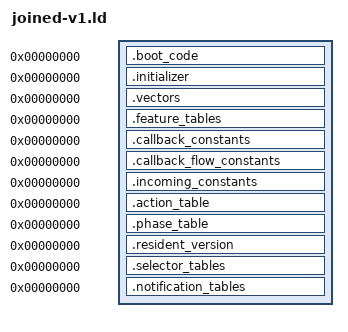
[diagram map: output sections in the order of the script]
OUTPUT_ARCH(riscv)
SECTIONS
{
 .boot_code 0 : SUBALIGN(2) { *(.boot_code)
  *(.text.tsl9_feature_external_a054)
  *(.text.tsl9_input_state_decoders_block_a066)
  *(.text.tsl9_input_state_decoders_block_a06a)
  *(.text.tsl9_input_state_decoders_block_a06e)
  *(.text.tsl9_input_state_decoders_block_a072)
  *(.text.tsl9_input_state_decoders_block_a082)
  *(.text.tsl9_input_state_decoders_block_a086)
  *(.text.tsl9_input_state_decoders_block_a08e)
  *(.text.tsl9_input_state_decoders_block_a098)
  *(.text.tsl9_input_state_decoders_block_a0a0)
  *(.text.tsl9_input_state_decoders_block_a0ac)
  *(.text.tsl9_input_state_decoders_block_a0ae)
  *(.text.tsl9_input_state_decoders_block_a0c4)
  *(.text.tsl9_input_state_decoders_block_a0c8)
  *(.text.tsl9_input_state_decoders_block_a0cc)
  *(.text.tsl9_input_state_decoders_block_a0d0)
  *(.text.tsl9_input_state_decoders_block_a0d4)
  *(.text.tsl9_input_state_decoders_block_a0e2)
  *(.text.tsl9_input_state_decoders_block_a0e6)
  *(.text.tsl9_input_state_decoders_block_a0ee)
  *(.text.tsl9_input_state_decoders_block_a100)
  *(.text.tsl9_input_state_decoders_block_a114)
  *(.text.tsl9_input_state_decoders_block_a132)
  *(.text.tsl9_input_state_decoders_block_a136)
  *(.text.tsl9_input_state_decoders_block_a140)
  *(.text.tsl9_input_state_decoders_block_a146)
  *(.text.tsl9_input_state_decoders_block_a168)
  *(.text.tsl9_input_state_decoders_block_a1ac)
  *(.text.tsl9_input_state_decoders_block_a1b6)
  *(.text.tsl9_input_state_decoders_block_a1b8)
  *(.text.tsl9_input_state_decoders_block_a1c8)
  *(.text.tsl9_input_state_decoders_block_a1d4)
  *(.text.tsl9_input_state_decoders_block_a1d6)
  *(.text.tsl9_input_state_decoders_block_a1e2)
  *(.text.tsl9_input_state_decoders_block_a1e8)
  *(.text.tsl9_input_state_decoders_block_a1f6)
  *(.text.tsl9_input_state_decoders_block_a1fa)
  *(.text.tsl9_input_state_decoders_block_a1fc)
  *(.text.tsl9_input_state_decoders_entry_a2ea)
  *(.text.tsl9_input_state_decoders_entry_aae2)
  *(.text.tsl9_input_state_decoders_entry_aaf2)
  *(.text.tsl9_feature_external_add6)
  *(.text.tsl9_input_state_decoders_block_ade8)
  *(.text.tsl9_input_state_decoders_block_adf2)
  *(.text.tsl9_input_state_decoders_block_adfc)
  *(.text.tsl9_input_state_decoders_block_ae02)
  *(.text.tsl9_input_state_decoders_block_ae06)
  *(.text.tsl9_input_state_decoders_block_ae0c)
  *(.text.tsl9_input_state_decoders_entry_ae0e)
  *(.text.tsl9_input_state_decoders_block_ae3a)
  *(.text.tsl9_input_state_decoders_block_ae4a)
  *(.text.tsl9_input_state_decoders_block_ae4c)
  *(.text.tsl9_input_state_decoders_block_ae58)
  *(.text.tsl9_input_state_decoders_block_ae62)
  *(.text.tsl9_input_state_decoders_block_ae70)
  *(.text.tsl9_input_state_decoders_block_ae84)
  *(.text.tsl9_input_state_decoders_block_ae86)
  *(.text.tsl9_input_state_decoders_block_ae8a)
  *(.text.tsl9_input_state_decoders_block_ae8e)
  *(.text.tsl9_input_state_decoders_block_ae9c)
  *(.text.tsl9_input_state_decoders_block_ae9e)
  *(.text.tsl9_input_state_decoders_block_aea8)
  *(.text.tsl9_input_state_decoders_block_aebc)
  *(.text.tsl9_input_state_decoders_block_aec2)
  *(.text.tsl9_input_state_decoders_block_aee0)
  *(.text.tsl9_input_state_decoders_block_aefe)
  *(.text.tsl9_input_state_decoders_block_af08)
  *(.text.tsl9_input_state_decoders_block_af0a)
  *(.text.tsl9_input_state_decoders_block_af0e)
  *(.text.tsl9_input_state_decoders_block_af12)
  *(.text.tsl9_input_state_decoders_block_af16)
  *(.text.tsl9_input_state_decoders_block_af1a)
  *(.text.tsl9_input_state_decoders_block_af1e)
  *(.text.tsl9_input_state_decoders_block_af2e)
  *(.text.tsl9_input_state_decoders_block_af40)
  *(.text.tsl9_input_state_decoders_block_af42)
  *(.text.tsl9_input_state_decoders_block_af48)
  *(.text.tsl9_input_state_decoders_block_af4c)
  *(.text.tsl9_input_state_decoders_block_af5c)
  *(.text.tsl9_input_state_decoders_block_af62)
  *(.text.tsl9_input_state_decoders_block_af66)
  *(.text.tsl9_input_state_decoders_block_af70)
  *(.text.tsl9_input_state_decoders_block_af84)
  *(.text.tsl9_input_state_decoders_block_af96)
  *(.text.tsl9_input_state_decoders_block_afc4)
  *(.text.tsl9_input_state_decoders_block_aff4)
  *(.text.tsl9_input_state_decoders_block_aff6)
  *(.text.tsl9_input_state_decoders_block_b000)
  *(.text.tsl9_input_state_decoders_block_b002)
  *(.text.tsl9_input_state_decoders_block_b004)
  *(.text.tsl9_input_state_decoders_block_b008)
  *(.text.tsl9_input_state_decoders_block_b016)
  *(.text.tsl9_input_state_decoders_block_b022)
  *(.text.tsl9_input_state_decoders_block_b034)
  *(.text.tsl9_feature_external_b036)
  *(.text.tsl9_input_state_decoders_block_b042)
  *(.text.tsl9_input_state_decoders_block_b044)
  *(.text.tsl9_input_state_decoders_block_b04a)
  *(.text.tsl9_input_state_decoders_block_b054)
  *(.text.tsl9_feature_external_b05c)
  *(.text.tsl9_input_state_decoders_block_b068)
  *(.text.tsl9_input_state_decoders_block_b06a)
  *(.text.tsl9_input_state_decoders_block_b070)
  *(.text.tsl9_input_state_decoders_block_b07a)
  *(.text.tsl9_feature_external_c472)
  *(.text.tsl9_input_state_decoders_block_c47a)
  *(.text.tsl9_input_state_decoders_block_c480)
  *(.text.tsl9_input_state_decoders_block_c482)
  *(.text.tsl9_input_state_decoders_block_c4a4)
  *(.text.tsl9_input_state_decoders_block_c4a6)
  *(.text.tsl9_input_state_decoders_block_c4b8)
  *(.text.tsl9_input_state_decoders_block_c4c2)
  *(.text.tsl9_input_state_decoders_block_c4c8)
  *(.text.tsl9_input_state_decoders_block_c4e4)
  *(.text.tsl9_input_state_decoders_block_c504)
  *(.text.tsl9_input_state_decoders_block_c506)
  *(.text.tsl9_input_state_decoders_block_c50a)
  *(.text.tsl9_input_state_decoders_block_c50c)
  *(.text.tsl9_input_state_decoders_block_c510)
  *(.text.tsl9_input_state_decoders_block_c51c)
  *(.text.tsl9_input_state_decoders_block_c524)
  *(.text.tsl9_input_state_decoders_block_c530)
  *(.text.tsl9_input_state_decoders_block_c538)
  *(.text.tsl9_input_state_decoders_block_c540)
  *(.text.tsl9_input_state_decoders_block_c54a)
  *(.text.tsl9_input_state_decoders_block_c552)
  *(.text.tsl9_input_state_decoders_block_c558)
  *(.text.tsl9_input_state_decoders_block_c56a)
  *(.text.tsl9_input_state_decoders_block_c57a)
  *(.text.tsl9_input_state_decoders_block_c58a)
  *(.text.tsl9_input_state_decoders_block_c59c)
  *(.text.tsl9_input_state_decoders_block_c5a8)
  *(.text.tsl9_input_state_decoders_block_c5b4)
  *(.text.tsl9_input_state_decoders_block_c5c0)
  *(.text.tsl9_input_state_decoders_block_c5d0)
  *(.text.tsl9_input_state_decoders_block_c5d8)
  *(.text.tsl9_input_state_decoders_block_c5e4)
  *(.text.tsl9_input_state_decoders_block_c5f4)
  *(.text.tsl9_input_state_decoders_block_c5fe)
  *(.text.tsl9_input_state_decoders_block_c602)
  *(.text.tsl9_feature_external_c60e)
  *(.text.tsl9_input_state_decoders_block_c616)
  *(.text.tsl9_input_state_decoders_block_c628)
  *(.text.tsl9_input_state_decoders_block_c636)
  *(.text.tsl9_input_state_decoders_block_c642)
  *(.text.tsl9_input_state_decoders_block_c646)
  *(.text.tsl9_input_state_decoders_block_c656)
  *(.text.tsl9_input_state_decoders_block_c666)
  *(.text.tsl9_input_state_decoders_block_c672)
  *(.text.tsl9_input_state_decoders_block_c676)
  *(.text.tsl9_input_state_decoders_block_c678)
  *(.text.tsl9_main_services_provider_c67a)
  *(.text.tsl9_input_state_decoders_block_c694)
  *(.text.tsl9_state_request_records_provider_d76c)
  *(.text.tsl9_input_state_decoders_block_d77c)
  *(.text.tsl9_input_state_decoders_block_d788)
  *(.text.tsl9_input_state_decoders_block_d794)
  *(.text.tsl9_input_state_decoders_block_d7a2)
  *(.text.tsl9_input_state_decoders_entry_d7a4)
  *(.text.tsl9_input_state_decoders_entry_d7b0)
  *(.text.tsl9_input_state_decoders_entry_d7bc)
  *(.text.tsl9_input_state_decoders_entry_d7c8)
 }
 .initializer 0 : SUBALIGN(4) { *(.initializer) }
 .vectors 0 : SUBALIGN(4) { *(.vectors) }
 .feature_tables 0 : SUBALIGN(4) { *(.feature_tables) }
 .callback_constants 0 : SUBALIGN(4) { *(.callback_constants) }
 .callback_flow_constants 0 : SUBALIGN(4) { *(.callback_flow_constants) }
 .incoming_constants 0 : SUBALIGN(4) { *(.incoming_constants) }
 .action_table 0 : SUBALIGN(4) { *(.action_table) }
 .phase_table 0 : SUBALIGN(4) { *(.phase_table) }
 .resident_version 0 : SUBALIGN(4) { *(.resident_version) }
 .selector_tables 0 : SUBALIGN(1) {
  *(.rodata.tsl9_feature_state_records_static_data_1a4e4)
  *(.rodata.tsl9_feature_state_records_static_data_1a518)
  *(.rodata.tsl9_feature_state_records_static_data_1a528)
  *(.rodata.tsl9_feature_state_records_static_data_1a538)
 }
 .notification_tables 0 : SUBALIGN(4) {
  *(.rodata.tsl9_selector_notifications_table_1a13c)
  *(.rodata.tsl9_selector_notifications_table_1a150)
  *(.rodata.tsl9_selector_notifications_table_1a1c8)
  *(.rodata.tsl9_selector_notifications_table_1a314)
  *(.rodata.tsl9_selector_notifications_table_1a33c)
 }
 /DISCARD/ : { *(.comment) *(.riscv.attributes) *(.llvm_addrsig) }
}
